AUTOSAR XML (schema 00049)
package /Application/DltConfig
  dlt log channel to process mapping DltLogChannelToProcessMapping_SC_PDW_FRONT_TO_SC_PDW_FRONT: dlt-log-channel=SC_PDW_FRONT, process=SC_PDW_FRONT
  dlt log channel to process mapping DltLogChannelToProcessMapping_SC_PDW_REAR_TO_SC_PDW_REAR: dlt-log-channel=SC_PDW_REAR, process=SC_PDW_REAR
package /Application/Executable
  executable SC_PDW_FRONT: category=APPLICATION_LEVEL, logging-behavior=USES-LOGGING, reporting-behavior=REPORTS-EXECUTION-STATE, version=1.0.0
    root sw component prototype RootSwComponent: application-type=SC_PDW_FRONT
  executable SC_PDW_REAR: category=APPLICATION_LEVEL, logging-behavior=USES-LOGGING, reporting-behavior=REPORTS-EXECUTION-STATE, version=1.0.0
    root sw component prototype RootSwComponent: application-type=SC_PDW_REAR
package /Application/Manifest
  6 x service instance to port prototype mapping:
    SC_PDW_FRONT_RootSwComponent_PdwFront: port-prototype=RootSwComponent.PdwFront, process=SC_PDW_FRONT, service-instance=EEVP_PDW_Provider_PdwFrontService
    SC_PDW_FRONT_RootSwComponent_UssFront: port-prototype=RootSwComponent.UssFront, process=SC_PDW_FRONT, service-instance=EEVP_PDW_Consumer_UssFrontInput
    SC_PDW_FRONT_RootSwComponent_VehicleInfo: port-prototype=RootSwComponent.VehicleInfo, process=SC_PDW_FRONT, service-instance=EEVP_PDW_Consumer_VehicleInfo
    SC_PDW_REAR_RootSwComponent_PdwRear: port-prototype=RootSwComponent.PdwRear, process=SC_PDW_REAR, service-instance=EEVP_PDW_Provider_PdwRearService
    SC_PDW_REAR_RootSwComponent_UssRear: port-prototype=RootSwComponent.UssRear, process=SC_PDW_REAR, service-instance=EEVP_PDW_Consumer_UssRearInput
    SC_PDW_REAR_RootSwComponent_VehicleInfo: port-prototype=RootSwComponent.VehicleInfo, process=SC_PDW_REAR, service-instance=EEVP_PDW_Consumer_VehicleInfo
package /Application/Package/SC_PDW_FRONT/SoftwareCluster_1_0_0
  software cluster SC_PDW_FRONT_SoftwareCluster: category=APPLICATION_LAYER, contained-ar-element=SC_PDW_FRONT, contained-package-element=[SC_PDW_FRONT_RootSwComponent_PdwFront, SC_PDW_FRONT_RootSwComponent_UssFront, SC_PDW_FRONT_RootSwComponent_VehicleInfo], contained-process=SC_PDW_FRONT, vendor-id=79, vendor-signature=ParaCertificate, version=1.0.0
package /Application/Package/SC_PDW_FRONT/SoftwarePackage
  software package SC_PDW_FRONT_SoftwarePackage: action-type=INSTALL, compressed-software-package-size=0, maximum-supported-ucm-version=1.0.0, minimum-supported-ucm-version=1.0.0, packager-id=79, packager-signature=ParaCertificate, post-verification-reboot=false, pre-activation-reboot=false, software-cluster=SC_PDW_FRONT_SoftwareCluster, uncompressed-software-cluster-size=0
package /Application/Package/SC_PDW_REAR/SoftwareCluster_1_0_0
  software cluster SC_PDW_REAR_SoftwareCluster: category=APPLICATION_LAYER, contained-ar-element=SC_PDW_REAR, contained-package-element=[SC_PDW_REAR_RootSwComponent_PdwRear, SC_PDW_REAR_RootSwComponent_UssRear, SC_PDW_REAR_RootSwComponent_VehicleInfo], contained-process=SC_PDW_REAR, vendor-id=79, vendor-signature=ParaCertificate, version=1.0.0
package /Application/Package/SC_PDW_REAR/SoftwarePackage
  software package SC_PDW_REAR_SoftwarePackage: action-type=INSTALL, compressed-software-package-size=0, maximum-supported-ucm-version=1.0.0, minimum-supported-ucm-version=1.0.0, packager-id=79, packager-signature=ParaCertificate, post-verification-reboot=false, pre-activation-reboot=false, software-cluster=SC_PDW_REAR_SoftwareCluster, uncompressed-software-cluster-size=0
package /Application/Process
  process SC_PDW_FRONT: executable=SC_PDW_FRONT, state-dependent-startup-config{function-group-state=[SC.On, SC.Verify], resource-group=DefaultResourceGroup, startup-config=DefaultStartupConfig}
    process state machine SC_PDW_FRONT: type=ProcessState
  process SC_PDW_REAR: executable=SC_PDW_REAR, state-dependent-startup-config{function-group-state=[SC.On, SC.Verify], resource-group=DefaultResourceGroup, startup-config=DefaultStartupConfig}
    process state machine SC_PDW_REAR: type=ProcessState
package /Application/SwComponent
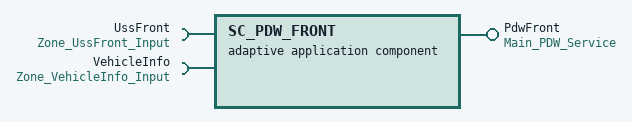
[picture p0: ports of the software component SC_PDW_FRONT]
  adaptive application sw component type SC_PDW_FRONT
    provide port PdwFront: provided-interface=Main_PDW_Service
    require port UssFront: required-interface=Zone_UssFront_Input
    require port VehicleInfo: required-interface=Zone_VehicleInfo_Input
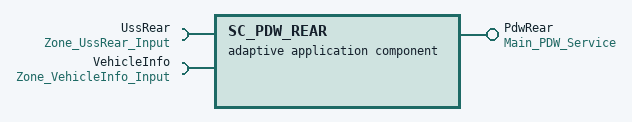
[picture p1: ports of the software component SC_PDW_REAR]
  adaptive application sw component type SC_PDW_REAR
    provide port PdwRear: provided-interface=Main_PDW_Service
    require port UssRear: required-interface=Zone_UssRear_Input
    require port VehicleInfo: required-interface=Zone_VehicleInfo_Input
